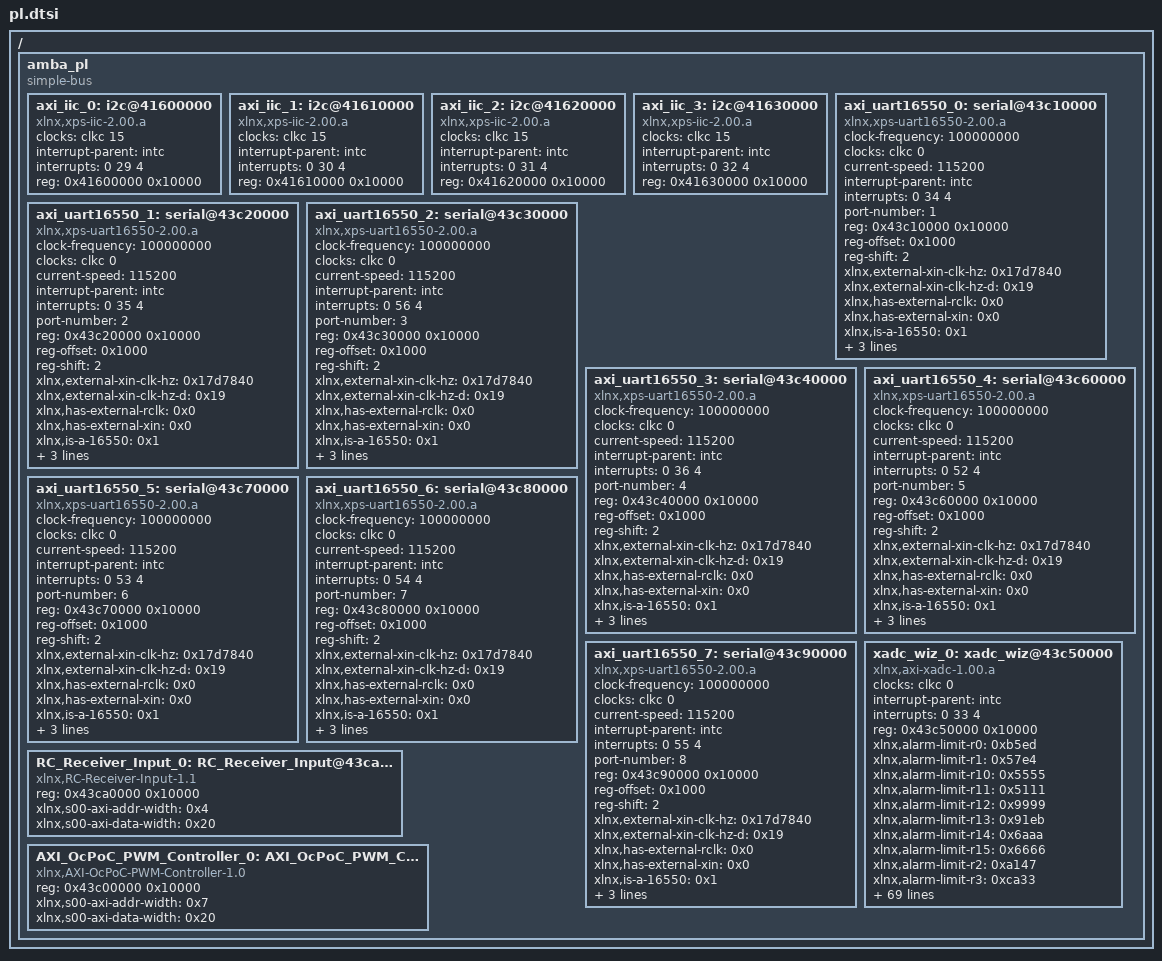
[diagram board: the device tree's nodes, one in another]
/*
 * CAUTION: This file is automatically generated by Xilinx.
 * Version:  
 * Today is: Wed Aug 02 15:55:20 2017
*/


/ {
	amba_pl: amba_pl {
		#address-cells = <1>;
		#size-cells = <1>;
		compatible = "simple-bus";
		ranges ;
		axi_iic_0: i2c@41600000 {
			#address-cells = <1>;
			#size-cells = <0>;
			clock-names = "ref_clk";
			clocks = "clkc 15";
			compatible = "xlnx,xps-iic-2.00.a";
			interrupt-parent = <&intc>;
			interrupts = <0 29 4>;
			reg = <0x41600000 0x10000>;
		};
		axi_iic_1: i2c@41610000 {
			#address-cells = <1>;
			#size-cells = <0>;
			clock-names = "ref_clk";
			clocks = "clkc 15";
			compatible = "xlnx,xps-iic-2.00.a";
			interrupt-parent = <&intc>;
			interrupts = <0 30 4>;
			reg = <0x41610000 0x10000>;
		};
		axi_iic_2: i2c@41620000 {
			#address-cells = <1>;
			#size-cells = <0>;
			clock-names = "ref_clk";
			clocks = "clkc 15";
			compatible = "xlnx,xps-iic-2.00.a";
			interrupt-parent = <&intc>;
			interrupts = <0 31 4>;
			reg = <0x41620000 0x10000>;
		};
		axi_iic_3: i2c@41630000 {
			#address-cells = <1>;
			#size-cells = <0>;
			clock-names = "ref_clk";
			clocks = "clkc 15";
			compatible = "xlnx,xps-iic-2.00.a";
			interrupt-parent = <&intc>;
			interrupts = <0 32 4>;
			reg = <0x41630000 0x10000>;
		};
		axi_uart16550_0: serial@43c10000 {
			clock-frequency = <100000000>;
			clock-names = "ref_clk";
			clocks = "clkc 0";
			compatible = "xlnx,xps-uart16550-2.00.a", "ns16550a";
			current-speed = <115200>;
			device_type = "serial";
			interrupt-parent = <&intc>;
			interrupts = <0 34 4>;
			port-number = <1>;
			reg = <0x43c10000 0x10000>;
			reg-offset = <0x1000>;
			reg-shift = <2>;
			xlnx,external-xin-clk-hz = <0x17d7840>;
			xlnx,external-xin-clk-hz-d = <0x19>;
			xlnx,has-external-rclk = <0x0>;
			xlnx,has-external-xin = <0x0>;
			xlnx,is-a-16550 = <0x1>;
			xlnx,s-axi-aclk-freq-hz-d = "100.0";
			xlnx,use-modem-ports = <0x1>;
			xlnx,use-user-ports = <0x1>;
		};
		axi_uart16550_1: serial@43c20000 {
			clock-frequency = <100000000>;
			clock-names = "ref_clk";
			clocks = "clkc 0";
			compatible = "xlnx,xps-uart16550-2.00.a", "ns16550a";
			current-speed = <115200>;
			device_type = "serial";
			interrupt-parent = <&intc>;
			interrupts = <0 35 4>;
			port-number = <2>;
			reg = <0x43c20000 0x10000>;
			reg-offset = <0x1000>;
			reg-shift = <2>;
			xlnx,external-xin-clk-hz = <0x17d7840>;
			xlnx,external-xin-clk-hz-d = <0x19>;
			xlnx,has-external-rclk = <0x0>;
			xlnx,has-external-xin = <0x0>;
			xlnx,is-a-16550 = <0x1>;
			xlnx,s-axi-aclk-freq-hz-d = "100.0";
			xlnx,use-modem-ports = <0x1>;
			xlnx,use-user-ports = <0x1>;
		};
		axi_uart16550_2: serial@43c30000 {
			clock-frequency = <100000000>;
			clock-names = "ref_clk";
			clocks = "clkc 0";
			compatible = "xlnx,xps-uart16550-2.00.a", "ns16550a";
			current-speed = <115200>;
			device_type = "serial";
			interrupt-parent = <&intc>;
			interrupts = <0 56 4>;
			port-number = <3>;
			reg = <0x43c30000 0x10000>;
			reg-offset = <0x1000>;
			reg-shift = <2>;
			xlnx,external-xin-clk-hz = <0x17d7840>;
			xlnx,external-xin-clk-hz-d = <0x19>;
			xlnx,has-external-rclk = <0x0>;
			xlnx,has-external-xin = <0x0>;
			xlnx,is-a-16550 = <0x1>;
			xlnx,s-axi-aclk-freq-hz-d = "100.0";
			xlnx,use-modem-ports = <0x1>;
			xlnx,use-user-ports = <0x1>;
		};
		axi_uart16550_3: serial@43c40000 {
			clock-frequency = <100000000>;
			clock-names = "ref_clk";
			clocks = "clkc 0";
			compatible = "xlnx,xps-uart16550-2.00.a", "ns16550a";
			current-speed = <115200>;
			device_type = "serial";
			interrupt-parent = <&intc>;
			interrupts = <0 36 4>;
			port-number = <4>;
			reg = <0x43c40000 0x10000>;
			reg-offset = <0x1000>;
			reg-shift = <2>;
			xlnx,external-xin-clk-hz = <0x17d7840>;
			xlnx,external-xin-clk-hz-d = <0x19>;
			xlnx,has-external-rclk = <0x0>;
			xlnx,has-external-xin = <0x0>;
			xlnx,is-a-16550 = <0x1>;
			xlnx,s-axi-aclk-freq-hz-d = "100.0";
			xlnx,use-modem-ports = <0x1>;
			xlnx,use-user-ports = <0x1>;
		};
		axi_uart16550_4: serial@43c60000 {
			clock-frequency = <100000000>;
			clock-names = "ref_clk";
			clocks = "clkc 0";
			compatible = "xlnx,xps-uart16550-2.00.a", "ns16550a";
			current-speed = <115200>;
			device_type = "serial";
			interrupt-parent = <&intc>;
			interrupts = <0 52 4>;
			port-number = <5>;
			reg = <0x43c60000 0x10000>;
			reg-offset = <0x1000>;
			reg-shift = <2>;
			xlnx,external-xin-clk-hz = <0x17d7840>;
			xlnx,external-xin-clk-hz-d = <0x19>;
			xlnx,has-external-rclk = <0x0>;
			xlnx,has-external-xin = <0x0>;
			xlnx,is-a-16550 = <0x1>;
			xlnx,s-axi-aclk-freq-hz-d = "100.0";
			xlnx,use-modem-ports = <0x1>;
			xlnx,use-user-ports = <0x1>;
		};
		axi_uart16550_5: serial@43c70000 {
			clock-frequency = <100000000>;
			clock-names = "ref_clk";
			clocks = "clkc 0";
			compatible = "xlnx,xps-uart16550-2.00.a", "ns16550a";
			current-speed = <115200>;
			device_type = "serial";
			interrupt-parent = <&intc>;
			interrupts = <0 53 4>;
			port-number = <6>;
			reg = <0x43c70000 0x10000>;
			reg-offset = <0x1000>;
			reg-shift = <2>;
			xlnx,external-xin-clk-hz = <0x17d7840>;
			xlnx,external-xin-clk-hz-d = <0x19>;
			xlnx,has-external-rclk = <0x0>;
			xlnx,has-external-xin = <0x0>;
			xlnx,is-a-16550 = <0x1>;
			xlnx,s-axi-aclk-freq-hz-d = "100.0";
			xlnx,use-modem-ports = <0x1>;
			xlnx,use-user-ports = <0x1>;
		};
		axi_uart16550_6: serial@43c80000 {
			clock-frequency = <100000000>;
			clock-names = "ref_clk";
			clocks = "clkc 0";
			compatible = "xlnx,xps-uart16550-2.00.a", "ns16550a";
			current-speed = <115200>;
			device_type = "serial";
			interrupt-parent = <&intc>;
			interrupts = <0 54 4>;
			port-number = <7>;
			reg = <0x43c80000 0x10000>;
			reg-offset = <0x1000>;
			reg-shift = <2>;
			xlnx,external-xin-clk-hz = <0x17d7840>;
			xlnx,external-xin-clk-hz-d = <0x19>;
			xlnx,has-external-rclk = <0x0>;
			xlnx,has-external-xin = <0x0>;
			xlnx,is-a-16550 = <0x1>;
			xlnx,s-axi-aclk-freq-hz-d = "100.0";
			xlnx,use-modem-ports = <0x1>;
			xlnx,use-user-ports = <0x1>;
		};
		axi_uart16550_7: serial@43c90000 {
			clock-frequency = <100000000>;
			clock-names = "ref_clk";
			clocks = "clkc 0";
			compatible = "xlnx,xps-uart16550-2.00.a", "ns16550a";
			current-speed = <115200>;
			device_type = "serial";
			interrupt-parent = <&intc>;
			interrupts = <0 55 4>;
			port-number = <8>;
			reg = <0x43c90000 0x10000>;
			reg-offset = <0x1000>;
			reg-shift = <2>;
			xlnx,external-xin-clk-hz = <0x17d7840>;
			xlnx,external-xin-clk-hz-d = <0x19>;
			xlnx,has-external-rclk = <0x0>;
			xlnx,has-external-xin = <0x0>;
			xlnx,is-a-16550 = <0x1>;
			xlnx,s-axi-aclk-freq-hz-d = "100.0";
			xlnx,use-modem-ports = <0x1>;
			xlnx,use-user-ports = <0x1>;
		};
		xadc_wiz_0: xadc_wiz@43c50000 {
			clock-names = "ref_clk";
			clocks = "clkc 0";
			compatible = "xlnx,axi-xadc-1.00.a";
			interrupt-parent = <&intc>;
			interrupts = <0 33 4>;
			reg = <0x43c50000 0x10000>;
			xlnx,alarm-limit-r0 = <0xb5ed>;
			xlnx,alarm-limit-r1 = <0x57e4>;
			xlnx,alarm-limit-r10 = <0x5555>;
			xlnx,alarm-limit-r11 = <0x5111>;
			xlnx,alarm-limit-r12 = <0x9999>;
			xlnx,alarm-limit-r13 = <0x91eb>;
			xlnx,alarm-limit-r14 = <0x6aaa>;
			xlnx,alarm-limit-r15 = <0x6666>;
			xlnx,alarm-limit-r2 = <0xa147>;
			xlnx,alarm-limit-r3 = <0xca33>;
			xlnx,alarm-limit-r4 = <0xa93a>;
			xlnx,alarm-limit-r5 = <0x52c6>;
			xlnx,alarm-limit-r6 = <0x9555>;
			xlnx,alarm-limit-r7 = <0xae4e>;
			xlnx,alarm-limit-r8 = <0x5999>;
			xlnx,alarm-limit-r9 = <0x5111>;
			xlnx,configuration-r0 = <0x0>;
			xlnx,configuration-r1 = <0x2100>;
			xlnx,configuration-r2 = <0x200>;
			xlnx,dclk-frequency = <0x32>;
			xlnx,external-mux = "none";
			xlnx,external-mux-channel = "VP_VN";
			xlnx,external-muxaddr-enable = <0x0>;
			xlnx,fifo-depth = <0x7>;
			xlnx,has-axi = <0x1>;
			xlnx,has-axi4stream = <0x0>;
			xlnx,has-busy = <0x1>;
			xlnx,has-channel = <0x1>;
			xlnx,has-convst = <0x0>;
			xlnx,has-convstclk = <0x0>;
			xlnx,has-dclk = <0x1>;
			xlnx,has-drp = <0x0>;
			xlnx,has-eoc = <0x1>;
			xlnx,has-eos = <0x1>;
			xlnx,has-external-mux = <0x0>;
			xlnx,has-jtagbusy = <0x0>;
			xlnx,has-jtaglocked = <0x0>;
			xlnx,has-jtagmodified = <0x0>;
			xlnx,has-ot-alarm = <0x1>;
			xlnx,has-reset = <0x0>;
			xlnx,has-temp-bus = <0x0>;
			xlnx,has-user-temp-alarm = <0x1>;
			xlnx,has-vbram-alarm = <0x0>;
			xlnx,has-vccaux-alarm = <0x1>;
			xlnx,has-vccddro-alarm = <0x1>;
			xlnx,has-vccint-alarm = <0x1>;
			xlnx,has-vccpaux-alarm = <0x1>;
			xlnx,has-vccpint-alarm = <0x1>;
			xlnx,has-vn = <0x1>;
			xlnx,has-vp = <0x1>;
			xlnx,include-intr = <0x1>;
			xlnx,sampling-rate = "961538.4615384615";
			xlnx,sequence-r0 = <0x101>;
			xlnx,sequence-r1 = <0x8000>;
			xlnx,sequence-r2 = <0x100>;
			xlnx,sequence-r3 = <0x8000>;
			xlnx,sequence-r4 = <0x0>;
			xlnx,sequence-r5 = <0x0>;
			xlnx,sequence-r6 = <0x0>;
			xlnx,sequence-r7 = <0x8000>;
			xlnx,sim-file-name = "design";
			xlnx,sim-file-rel-path = "./";
			xlnx,sim-file-sel = "Default";
			xlnx,vaux0 = <0x0>;
			xlnx,vaux1 = <0x0>;
			xlnx,vaux10 = <0x0>;
			xlnx,vaux11 = <0x0>;
			xlnx,vaux12 = <0x0>;
			xlnx,vaux13 = <0x0>;
			xlnx,vaux14 = <0x0>;
			xlnx,vaux15 = <0x1>;
			xlnx,vaux2 = <0x0>;
			xlnx,vaux3 = <0x0>;
			xlnx,vaux4 = <0x0>;
			xlnx,vaux5 = <0x0>;
			xlnx,vaux6 = <0x0>;
			xlnx,vaux7 = <0x0>;
			xlnx,vaux8 = <0x0>;
			xlnx,vaux9 = <0x0>;
		};
		RC_Receiver_Input_0: RC_Receiver_Input@43ca0000 {
			compatible = "xlnx,RC-Receiver-Input-1.1";
			reg = <0x43ca0000 0x10000>;
			xlnx,s00-axi-addr-width = <0x4>;
			xlnx,s00-axi-data-width = <0x20>;
		};
		AXI_OcPoC_PWM_Controller_0: AXI_OcPoC_PWM_Controller@43c00000 {
			compatible = "xlnx,AXI-OcPoC-PWM-Controller-1.0";
			reg = <0x43c00000 0x10000>;
			xlnx,s00-axi-addr-width = <0x7>;
			xlnx,s00-axi-data-width = <0x20>;
		};
	};
};
